AUTOSAR XML (schema 4.0)
package /SwComponentTypes
  application sw component type SensorInputSWC
    provide port Pp_ObjectCandidateList
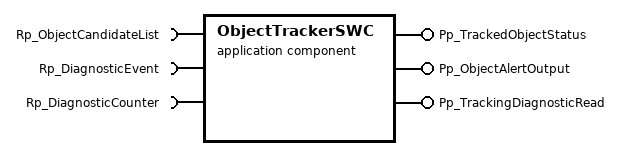
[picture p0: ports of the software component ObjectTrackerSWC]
  application sw component type ObjectTrackerSWC
    require port Rp_ObjectCandidateList
    provide port Pp_TrackedObjectStatus
    provide port Pp_ObjectAlertOutput
    require port Rp_DiagnosticEvent
    require port Rp_DiagnosticCounter
    provide port Pp_TrackingDiagnosticRead
